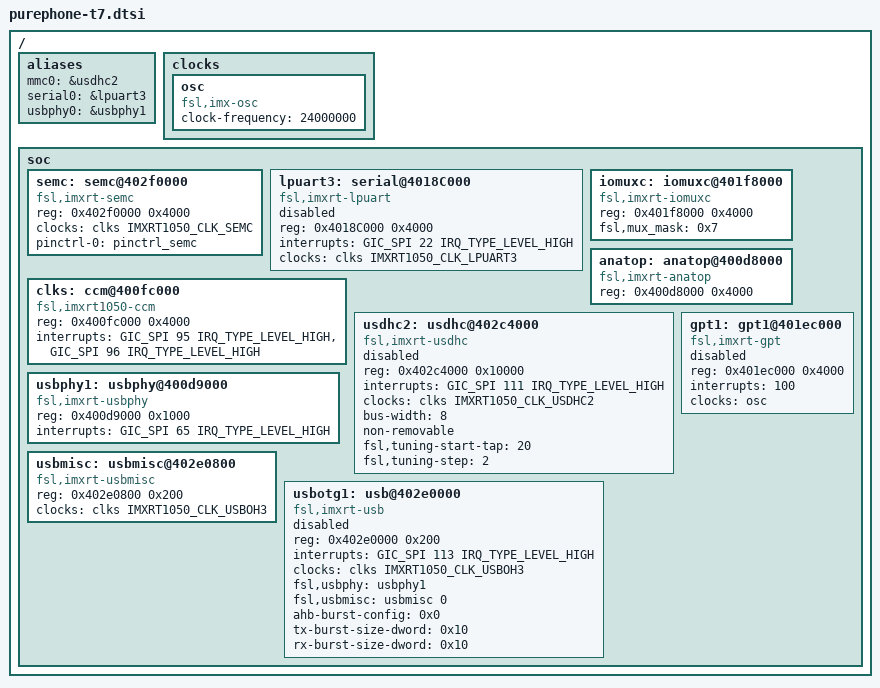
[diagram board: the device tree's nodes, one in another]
// Copyright (c) 2017-2022, Mudita Sp. z.o.o. All rights reserved.
// For licensing, see https://github.com/mudita/MuditaOS/LICENSE.md

#include "armv7-m.dtsi"
#include <dt-bindings/interrupt-controller/arm-gic.h>
#include <dt-bindings/clock/imxrt1050-clock.h>
#include <dt-bindings/gpio/gpio.h>
#include <dt-bindings/memory/imxrt-sdram.h>

/ {
	#address-cells = <1>;
	#size-cells = <1>;

	aliases {
		mmc0 = &usdhc2;
		serial0 = &lpuart3;
		usbphy0 = &usbphy1;
	};

	clocks {
		osc: osc {
			compatible = "fsl,imx-osc", "fixed-clock";
			#clock-cells = <0>;
			clock-frequency = <24000000>;
		};
	};

	soc {
		semc: semc@402f0000 {
			compatible = "fsl,imxrt-semc";
			reg = <0x402f0000 0x4000>;
			clocks = <&clks IMXRT1050_CLK_SEMC>;
			pinctrl-0 = <&pinctrl_semc>;
			pinctrl-names = "default";
			status = "okay";
		};

		lpuart3: serial@4018C000 {
			compatible = "fsl,imxrt-lpuart";
			reg = <0x4018C000 0x4000>;
			interrupts = <GIC_SPI 22 IRQ_TYPE_LEVEL_HIGH>;
            clocks = <&clks IMXRT1050_CLK_LPUART3>;
			clock-names = "per";
			status = "disabled";
		};

		iomuxc: iomuxc@401f8000 {
			compatible = "fsl,imxrt-iomuxc";
			reg = <0x401f8000 0x4000>;
			fsl,mux_mask = <0x7>;
		};

		anatop: anatop@400d8000 {
			compatible = "fsl,imxrt-anatop";
			reg = <0x400d8000 0x4000>;
		};

		clks: ccm@400fc000 {
			compatible = "fsl,imxrt1050-ccm";
			reg = <0x400fc000 0x4000>;
			interrupts = <GIC_SPI 95 IRQ_TYPE_LEVEL_HIGH>,
				     <GIC_SPI 96 IRQ_TYPE_LEVEL_HIGH>;
			#clock-cells = <1>;
		};

		usdhc2: usdhc@402c4000 {
			compatible = "fsl,imxrt-usdhc";
			reg = <0x402c4000 0x10000>;
			interrupts = <GIC_SPI 111 IRQ_TYPE_LEVEL_HIGH>;
			clocks = <&clks IMXRT1050_CLK_USDHC2>;
			clock-names = "per";
			bus-width = <8>;
            non-removable;
			fsl,tuning-start-tap = <20>;
			fsl,tuning-step= <2>;
			status = "disabled";
		};

        gpt1: gpt1@401ec000 {
			compatible = "fsl,imxrt-gpt";
			reg = <0x401ec000 0x4000>;
			interrupts = <100>;
			clocks = <&osc>;
			status = "disabled";
		};

		usbphy1: usbphy@400d9000 {
			compatible = "fsl,imxrt-usbphy";
			reg = <0x400d9000 0x1000>;
			interrupts = <GIC_SPI 65 IRQ_TYPE_LEVEL_HIGH>;
		};

		usbmisc: usbmisc@402e0800 {
			#index-cells = <1>;
			compatible = "fsl,imxrt-usbmisc";
			reg = <0x402e0800 0x200>;
			clocks = <&clks IMXRT1050_CLK_USBOH3>;
		};

		usbotg1: usb@402e0000 {
			compatible = "fsl,imxrt-usb", "fsl,imx27-usb";
			reg = <0x402e0000 0x200>;
			interrupts = <GIC_SPI 113 IRQ_TYPE_LEVEL_HIGH>;
			clocks = <&clks IMXRT1050_CLK_USBOH3>;
			fsl,usbphy = <&usbphy1>;
			fsl,usbmisc = <&usbmisc 0>;
			ahb-burst-config = <0x0>;
			tx-burst-size-dword = <0x10>;
			rx-burst-size-dword = <0x10>;
			status = "disabled";
		};
	};
};
